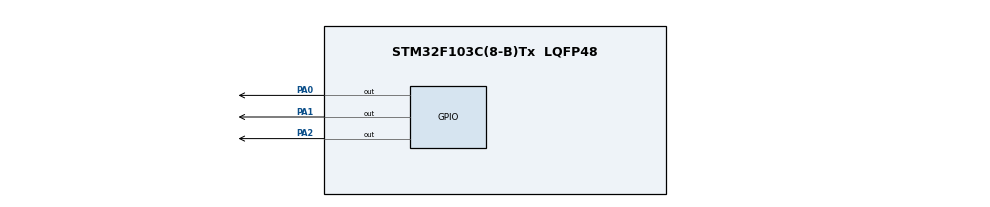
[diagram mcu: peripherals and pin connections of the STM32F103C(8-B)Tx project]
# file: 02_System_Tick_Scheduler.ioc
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Mcu.Family=STM32F1
Mcu.Name=STM32F103C(8-B)Tx
Mcu.Package=LQFP48
NVIC.PriorityGroup=NVIC_PRIORITYGROUP_4
NVIC.TIM2_IRQn=true\:0\:0\:false\:false\:true\:true\:true\:true
PA0-WKUP.Signal=GPIO_Output
PA1.Signal=GPIO_Output
PA2.Signal=GPIO_Output
PD0-OSC_IN.Mode=HSE-External-Oscillator
PD0-OSC_IN.Signal=RCC_OSC_IN
PD1-OSC_OUT.Mode=HSE-External-Oscillator
PD1-OSC_OUT.Signal=RCC_OSC_OUT
ProjectManager.HeapSize=0x200
ProjectManager.StackSize=0x400
ProjectManager.TargetToolchain=STM32CubeIDE
RCC.APB1Freq_Value=8000000
RCC.APB2Freq_Value=8000000
TIM2.Period=9
TIM2.Prescaler=7199
VP_SYS_VS_ND.Mode=No_Debug
VP_TIM2_VS_ClockSourceINT.Mode=Internal
board=custom

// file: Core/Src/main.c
/* USER CODE BEGIN Header */
/**
  ******************************************************************************
  * @file           : main.c
  * @brief          : Main program body
  ******************************************************************************
  * @attention
  *
  * Copyright (c) 2026 STMicroelectronics.
  * All rights reserved.
  *
  * This software is licensed under terms that can be found in the LICENSE file
  * in the root directory of this software component.
  * If no LICENSE file comes with this software, it is provided AS-IS.
  *
  ******************************************************************************
  */
/* USER CODE END Header */
#include "main.h"
#include "tim.h"
#include "gpio.h"

/* USER CODE BEGIN PV */
volatile uint32_t system_tick = 0;
uint32_t last_led1 = 0;
uint32_t last_led2 = 0;
uint32_t last_led3 = 0;
/* USER CODE END PV */

void SystemClock_Config(void);

int main(void)
{

  /* MCU Configuration--------------------------------------------------------*/

  /* Reset of all peripherals, Initializes the Flash interface and the Systick. */
  HAL_Init();

  /* Configure the system clock */
  SystemClock_Config();

  /* Initialize all configured peripherals */
  MX_GPIO_Init();
  MX_TIM2_Init();
  /* USER CODE BEGIN 2 */
  HAL_TIM_Base_Start_IT(&htim2);
  /* USER CODE END 2 */

  /* Infinite loop */
  while (1)
  {

    /* USER CODE BEGIN 3 */
	  if (system_tick - last_led1 >= 200)
	  {
	      HAL_GPIO_TogglePin(GPIOA, GPIO_PIN_0);
	      last_led1 = system_tick;
	  }

	  if (system_tick - last_led2 >= 500)
	  {
	      HAL_GPIO_TogglePin(GPIOA, GPIO_PIN_1);
	      last_led2 = system_tick;
	  }

	  if (system_tick - last_led3 >= 1000)
	  {
	      HAL_GPIO_TogglePin(GPIOA, GPIO_PIN_2);
	      last_led3 = system_tick;
	  }
  }
  /* USER CODE END 3 */
}

void SystemClock_Config(void)
{
  RCC_OscInitTypeDef RCC_OscInitStruct = {0};
  RCC_ClkInitTypeDef RCC_ClkInitStruct = {0};

  /** Initializes the RCC Oscillators according to the specified parameters
  * in the RCC_OscInitTypeDef structure.
  */
  RCC_OscInitStruct.OscillatorType = RCC_OSCILLATORTYPE_HSI;
  RCC_OscInitStruct.HSIState = RCC_HSI_ON;
  RCC_OscInitStruct.HSICalibrationValue = RCC_HSICALIBRATION_DEFAULT;
  RCC_OscInitStruct.PLL.PLLState = RCC_PLL_NONE;
  if (HAL_RCC_OscConfig(&RCC_OscInitStruct) != HAL_OK)
  {
    Error_Handler();
  }

  /** Initializes the CPU, AHB and APB buses clocks
  */
  RCC_ClkInitStruct.ClockType = RCC_CLOCKTYPE_HCLK|RCC_CLOCKTYPE_SYSCLK
                              |RCC_CLOCKTYPE_PCLK1|RCC_CLOCKTYPE_PCLK2;
  RCC_ClkInitStruct.SYSCLKSource = RCC_SYSCLKSOURCE_HSI;
  RCC_ClkInitStruct.AHBCLKDivider = RCC_SYSCLK_DIV1;
  RCC_ClkInitStruct.APB1CLKDivider = RCC_HCLK_DIV1;
  RCC_ClkInitStruct.APB2CLKDivider = RCC_HCLK_DIV1;

  if (HAL_RCC_ClockConfig(&RCC_ClkInitStruct, FLASH_LATENCY_0) != HAL_OK)
  {
    Error_Handler();
  }
}

/* USER CODE BEGIN 4 */
void HAL_TIM_PeriodElapsedCallback(TIM_HandleTypeDef *htim)
{
    if (htim->Instance == TIM2)
    {
        system_tick++;
    }
}
/* USER CODE END 4 */

void Error_Handler(void)
{
  __disable_irq();
  while (1)
  {
  }
}
